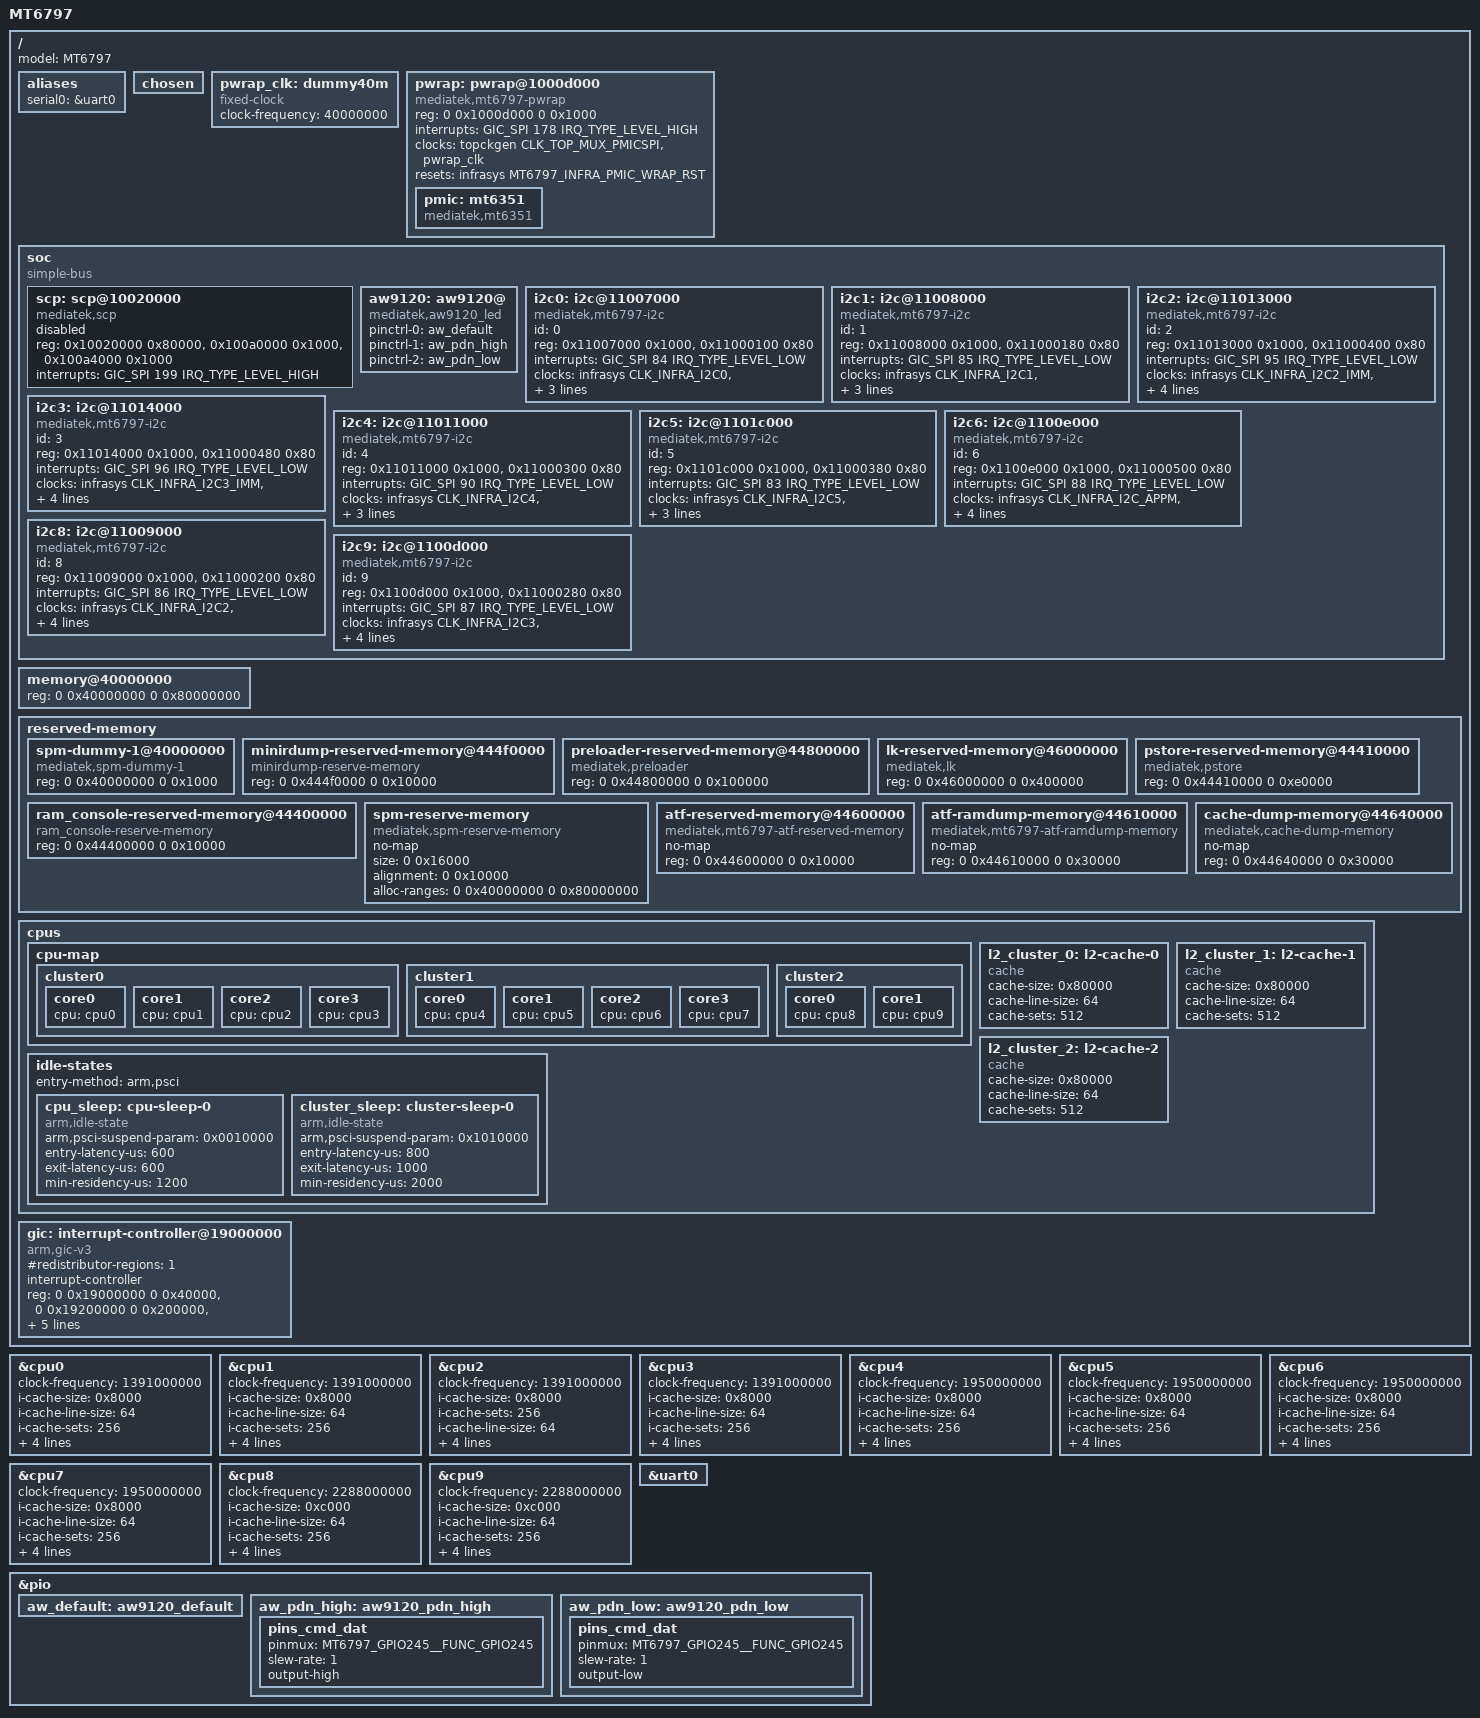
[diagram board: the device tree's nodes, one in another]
// SPDX-License-Identifier: GPL-2.0
/dts-v1/;

#include "mt6797.dtsi"
#include "mt6351.dtsi"
#include <dt-bindings/interrupt-controller/arm-gic.h>
#include <dt-bindings/power/mt6797-power.h>
#include <dt-bindings/reset/mt6797-resets.h>

/ {
	model = "MT6797";

	aliases {
		serial0 = &uart0;
	};

	chosen {
		// Specifying cmdline here is useless, since they are
		// overwritten by LK. CMDLINE is overridden in kernel config.
	};

	// pwrap needs a pwrap clock, but MT6797 does not have one. Make a
	// fake clock to sate the module's hunger.
	pwrap_clk: dummy40m {
		compatible = "fixed-clock";
		clock-frequency = <40000000>;
		#clock-cells = <0>;
	};

	pwrap: pwrap@1000d000 {
		compatible = "mediatek,mt6797-pwrap";
		reg = <0 0x1000d000 0 0x1000>;
		reg-names = "pwrap";
		interrupts = <GIC_SPI 178 IRQ_TYPE_LEVEL_HIGH>;
		clocks = <&topckgen CLK_TOP_MUX_PMICSPI>, <&pwrap_clk>;
		clock-names = "spi", "wrap";
		resets = <&infrasys MT6797_INFRA_PMIC_WRAP_RST>;
		reset-names = "pwrap";
		pmic: mt6351 {
			compatible = "mediatek,mt6351";
		};
	};


	soc {
		compatible = "simple-bus";
		#address-cells = <1>;
		#size-cells = <1>;
		ranges = <0 0 0 0xffffffff>;

		// This node is required by MediaTek's LK bootloader.
		scp: scp@10020000 {
			compatible = "mediatek,scp";
			status = "disabled";
			reg = <0x10020000 0x80000>,
				<0x100a0000 0x1000>,
				<0x100a4000 0x1000>;
			interrupts = <GIC_SPI 199 IRQ_TYPE_LEVEL_HIGH>;
		};

		aw9120: aw9120@ {
			compatible = "mediatek,aw9120_led";
		};

		i2c0:i2c@11007000 {
			compatible = "mediatek,mt6797-i2c";
			id = <0>;
			reg = <0x11007000 0x1000>,
				<0x11000100 0x80>;
			interrupts = <GIC_SPI 84 IRQ_TYPE_LEVEL_LOW>;
			clocks = <&infrasys CLK_INFRA_I2C0>, <&infrasys CLK_INFRA_AP_DMA>;
			clock-names = "main", "dma";
			clock-div = <10>;
		};

		i2c1:i2c@11008000 {
			compatible = "mediatek,mt6797-i2c";
			id = <1>;
			reg = <0x11008000 0x1000>,
				<0x11000180 0x80>;
			interrupts = <GIC_SPI 85 IRQ_TYPE_LEVEL_LOW>;
			clocks = <&infrasys CLK_INFRA_I2C1>, <&infrasys CLK_INFRA_AP_DMA>;
			clock-names = "main", "dma";
			clock-div = <10>;
		};

		i2c2:i2c@11013000 {
			compatible = "mediatek,mt6797-i2c";
			id = <2>;
			reg = <0x11013000 0x1000>,
				<0x11000400 0x80>;
			interrupts = <GIC_SPI 95 IRQ_TYPE_LEVEL_LOW>;
			clocks = <&infrasys CLK_INFRA_I2C2_IMM>, <&infrasys CLK_INFRA_AP_DMA>,
						<&infrasys CLK_INFRA_I2C2_ARB>;
			clock-names = "main", "dma", "arb";
			clock-div = <10>;
		};

		i2c3:i2c@11014000 {
			compatible = "mediatek,mt6797-i2c";
			id = <3>;
			reg = <0x11014000 0x1000>,
				<0x11000480 0x80>;
			interrupts = <GIC_SPI 96 IRQ_TYPE_LEVEL_LOW>;
			clocks = <&infrasys CLK_INFRA_I2C3_IMM>, <&infrasys CLK_INFRA_AP_DMA>,
						<&infrasys CLK_INFRA_I2C3_ARB>;
			clock-names = "main", "dma", "arb";
			clock-div = <10>;
		};

		i2c4:i2c@11011000 {
			compatible = "mediatek,mt6797-i2c";
			id = <4>;
			reg = <0x11011000 0x1000>,
				<0x11000300 0x80>;
			interrupts = <GIC_SPI 90 IRQ_TYPE_LEVEL_LOW>;
			clocks = <&infrasys CLK_INFRA_I2C4>, <&infrasys CLK_INFRA_AP_DMA>;
			clock-names = "main", "dma";
			clock-div = <10>;
		};

		i2c5:i2c@1101c000 {
			compatible = "mediatek,mt6797-i2c";
			id = <5>;
			reg = <0x1101c000 0x1000>,
				<0x11000380 0x80>;
			interrupts = <GIC_SPI 83 IRQ_TYPE_LEVEL_LOW>;
			clocks = <&infrasys CLK_INFRA_I2C5>, <&infrasys CLK_INFRA_AP_DMA>;
			clock-names = "main", "dma";
			clock-div = <10>;
		};

		i2c6:i2c@1100e000 {
			compatible = "mediatek,mt6797-i2c";
			id = <6>;
			reg = <0x1100e000 0x1000>,
				<0x11000500 0x80>;
			interrupts = <GIC_SPI 88 IRQ_TYPE_LEVEL_LOW>;
			clocks = <&infrasys CLK_INFRA_I2C_APPM>, <&infrasys CLK_INFRA_AP_DMA>;
			clock-names = "main", "dma";
			clock-div = <10>;
			mediatek,appm_used;
		};

/* Dissabled for now, needs rt5737
		i2c7:i2c@11010000 {
			compatible = "mediatek,mt6797-i2c";
			id = <7>;
			reg = <0x11010000 0x1000>,
				<0x11000580 0x80>;
			interrupts = <GIC_SPI 89 IRQ_TYPE_LEVEL_LOW>;
			clocks = <&infrasys CLK_INFRA_I2C_GPUPM>, <&infrasys CLK_INFRA_AP_DMA>;
			clock-names = "main", "dma";
			clock-div = <10>;
			mediatek,gpupm_used;

			rt5735@1c {
				status = "ok";
				compatible = "rt,rt5735-regulator";
				reg = <0x1c>;
				//rt,pgdvs;
				//rt,pgdcdc;
				rt,dvs_up = <0x6>;
				rt,dvs_down = <0x1>;
				//rt,dvs_mode;
				rt,ioc = <0x1>;
				rt,tpwth = <0x2>;
				rt,rearm;
			};
		};
*/
		i2c8:i2c@11009000 {
			compatible = "mediatek,mt6797-i2c";
			id = <8>;
			reg = <0x11009000 0x1000>,
				<0x11000200 0x80>;
			interrupts = <GIC_SPI 86 IRQ_TYPE_LEVEL_LOW>;
			clocks = <&infrasys CLK_INFRA_I2C2>, <&infrasys CLK_INFRA_AP_DMA>,
						<&infrasys CLK_INFRA_I2C2_ARB>;
			clock-names = "main", "dma", "arb";
			clock-div = <10>;
			mediatek,buffermode_used;
		};

		i2c9:i2c@1100d000 {
			compatible = "mediatek,mt6797-i2c";
			id = <9>;
			reg = <0x1100d000 0x1000>,
				<0x11000280 0x80>;
			interrupts = <GIC_SPI 87 IRQ_TYPE_LEVEL_LOW>;
			clocks = <&infrasys CLK_INFRA_I2C3>, <&infrasys CLK_INFRA_AP_DMA>,
						<&infrasys CLK_INFRA_I2C3_ARB>;
			clock-names = "main", "dma", "arb";
			clock-div = <10>;
			mediatek,buffermode_used;
		};

	};

	memory@40000000 {
		device_type = "memory";
		// It won't matter much what we write here, since the bootloader
		// overwrites the reg option anyway.
		reg = <0 0x40000000 0 0x80000000>;
	};

	reserved-memory {
		#address-cells = <2>;
		#size-cells = <2>;
		ranges;

		spm-dummy-1@40000000 {
			compatible = "mediatek,spm-dummy-1";
			reg = <0 0x40000000 0 0x1000>;
		};

		minirdump-reserved-memory@444f0000 {
			compatible = "minirdump-reserve-memory";
			reg = <0 0x444f0000 0 0x10000>;
		};

		preloader-reserved-memory@44800000 {
			compatible = "mediatek,preloader";
			reg = <0 0x44800000 0 0x100000>;
		};

		lk-reserved-memory@46000000 {
			compatible = "mediatek,lk";
			reg = <0 0x46000000 0 0x400000>;
		};

		ram_console-reserved-memory@44400000 {
			compatible = "ram_console-reserve-memory";
			reg = <0 0x44400000 0 0x10000>;
		};

		pstore-reserved-memory@44410000 {
			compatible = "mediatek,pstore";
			reg = <0 0x44410000 0 0xe0000>;
			/*console-size = <0 0x40000>;*/
		};

		spm-reserve-memory {
			compatible = "mediatek,spm-reserve-memory";
			no-map;
			size = <0 0x16000>; /* PCM_FIRMWARE_SIZE * DYNA_LOAD_PCM_MAX = 8K * 11 */
			alignment = <0 0x10000>;
			alloc-ranges = <0 0x40000000 0 0x80000000>;
		};

		atf-reserved-memory@44600000 {
			compatible = "mediatek,mt6797-atf-reserved-memory";
			no-map;
			reg = <0 0x44600000 0 0x10000>;
		};

		atf-ramdump-memory@44610000 {
			compatible = "mediatek,mt6797-atf-ramdump-memory";
			no-map;
			reg = <0 0x44610000 0 0x30000>;
		};

		cache-dump-memory@44640000 {
			compatible = "mediatek,cache-dump-memory";
			no-map;
			reg = <0 0x44640000 0 0x30000>;
		};

	};

	cpus {
		cpu-map {
			cluster0 {
				 core0 { cpu = <&cpu0>; };
				 core1 { cpu = <&cpu1>; };
				 core2 { cpu = <&cpu2>; };
				 core3 { cpu = <&cpu3>; };
			};
			cluster1 {
				 core0 { cpu = <&cpu4>; };
				 core1 { cpu = <&cpu5>; };
				 core2 { cpu = <&cpu6>; };
				 core3 { cpu = <&cpu7>; };
			};
			cluster2 {
				 core0 { cpu = <&cpu8>; };
				 core1 { cpu = <&cpu9>; };
			};
		};

		idle-states {
			entry-method = "arm,psci";

			cpu_sleep: cpu-sleep-0 {
				compatible = "arm,idle-state";
				arm,psci-suspend-param = <0x0010000>;
				entry-latency-us = <600>;
				exit-latency-us = <600>;
				min-residency-us = <1200>;
			};
			cluster_sleep: cluster-sleep-0 {
				compatible = "arm,idle-state";
				arm,psci-suspend-param = <0x1010000>;
				entry-latency-us = <800>;
				exit-latency-us = <1000>;
				min-residency-us = <2000>;
			};
		};

		l2_cluster_0: l2-cache-0 {
			compatible = "cache";
			cache-size = <0x80000>;
			cache-line-size = <64>;
			cache-sets = <512>;
		};

		l2_cluster_1: l2-cache-1 {
			compatible = "cache";
			cache-size = <0x80000>;
			cache-line-size = <64>;
			cache-sets = <512>;
		};

		l2_cluster_2: l2-cache-2 {
			compatible = "cache";
			cache-size = <0x80000>;
			cache-line-size = <64>;
			cache-sets = <512>;
		};
	};

	gic: interrupt-controller@19000000 {
		compatible = "arm,gic-v3";
		#interrupt-cells = <3>;
		#address-cells = <2>;
		#size-cells = <2>;
		#redistributor-regions = <1>;
		interrupt-controller;
		reg = <0 0x19000000 0 0x40000>, // distributor
			<0 0x19200000 0 0x200000>, // redistributor
			<0 0x10220620 0 0x001000>, // INTPOL0
			<0 0x10220690 0 0x001000>; // INTPOL1
		interrupts = <GIC_PPI 9 IRQ_TYPE_LEVEL_HIGH>;
		mediatek,wdt_irq = <169>;
		mediatek,reg_len_pol0 = <8>; // 8*32 irq polarity setting in INTPOL0
	};

};

// clock-frequency must be specified for each CPU. If it is omitted, MediaTek's
// LK bootloader might read uninitialized memory and perhaps overwrite some
// random properties in the device tree.

// Slow Cortex-A53 cluster
&cpu0 {
	clock-frequency = <1391000000>;
	//cpu-idle-states = <&cpu_sleep &cluster_sleep>;
	i-cache-size = <0x8000>;
	i-cache-line-size = <64>;
	i-cache-sets = <256>;
	d-cache-size = <0x8000>;
	d-cache-line-size = <64>;
	d-cache-sets = <128>;
	next-level-cache = <&l2_cluster_0>;
};
&cpu1 {
	clock-frequency = <1391000000>;
	//cpu-idle-states = <&cpu_sleep &cluster_sleep>;
	i-cache-size = <0x8000>;
	i-cache-line-size = <64>;
	i-cache-sets = <256>;
	d-cache-size = <0x8000>;
	d-cache-line-size = <64>;
	d-cache-sets = <128>;
	next-level-cache = <&l2_cluster_0>;
};
&cpu2 {
	clock-frequency = <1391000000>;
	//cpu-idle-states = <&cpu_sleep &cluster_sleep>;
	i-cache-size = <0x8000>;
	i-cache-sets = <256>;
	i-cache-line-size = <64>;
	d-cache-size = <0x8000>;
	d-cache-line-size = <64>;
	d-cache-sets = <128>;
	next-level-cache = <&l2_cluster_0>;
};
&cpu3 {
	clock-frequency = <1391000000>;
	//cpu-idle-states = <&cpu_sleep &cluster_sleep>;
	i-cache-size = <0x8000>;
	i-cache-line-size = <64>;
	i-cache-sets = <256>;
	d-cache-size = <0x8000>;
	d-cache-line-size = <64>;
	d-cache-sets = <128>;
	next-level-cache = <&l2_cluster_0>;
};

// Fast Cortex-A53 cluster
&cpu4 {
	clock-frequency = <1950000000>;
	//cpu-idle-states = <&cpu_sleep &cluster_sleep>;
	i-cache-size = <0x8000>;
	i-cache-line-size = <64>;
	i-cache-sets = <256>;
	d-cache-size = <0x8000>;
	d-cache-line-size = <64>;
	d-cache-sets = <128>;
	next-level-cache = <&l2_cluster_1>;
};
&cpu5 {
	clock-frequency = <1950000000>;
	//cpu-idle-states = <&cpu_sleep &cluster_sleep>;
	i-cache-size = <0x8000>;
	i-cache-line-size = <64>;
	i-cache-sets = <256>;
	d-cache-size = <0x8000>;
	d-cache-line-size = <64>;
	d-cache-sets = <128>;
	next-level-cache = <&l2_cluster_1>;
};
&cpu6 {
	clock-frequency = <1950000000>;
	//cpu-idle-states = <&cpu_sleep &cluster_sleep>;
	i-cache-size = <0x8000>;
	i-cache-line-size = <64>;
	i-cache-sets = <256>;
	d-cache-size = <0x8000>;
	d-cache-line-size = <64>;
	d-cache-sets = <128>;
	next-level-cache = <&l2_cluster_1>;
};
&cpu7 {
	clock-frequency = <1950000000>;
	//cpu-idle-states = <&cpu_sleep &cluster_sleep>;
	i-cache-size = <0x8000>;
	i-cache-line-size = <64>;
	i-cache-sets = <256>;
	d-cache-size = <0x8000>;
	d-cache-line-size = <64>;
	d-cache-sets = <128>;
	next-level-cache = <&l2_cluster_1>;
};

// Fast Cortex-A72 cluster
&cpu8 {
	clock-frequency = <2288000000>;
	//cpu-idle-states = <&cpu_sleep &cluster_sleep>;

	i-cache-size = <0xc000>;
	i-cache-line-size = <64>;
	i-cache-sets = <256>;

	d-cache-size = <0x8000>;
	d-cache-line-size = <64>;
	d-cache-sets = <256>;
	next-level-cache = <&l2_cluster_2>;
};
&cpu9 {
	clock-frequency = <2288000000>;
	//cpu-idle-states = <&cpu_sleep &cluster_sleep>;

	i-cache-size = <0xc000>;
	i-cache-line-size = <64>;
	i-cache-sets = <256>;

	d-cache-size = <0x8000>;
	d-cache-line-size = <64>;
	d-cache-sets = <256>;
	next-level-cache = <&l2_cluster_2>;
};

&uart0 {
	status = "okay";
};

&i2c0 {
	pinctrl-names = "default";
	pinctrl-0 = <&i2c_pins_0>;
	status = "okay";
};

&i2c1 {
	pinctrl-names = "default";
	pinctrl-0 = <&i2c_pins_1>;
	status = "okay";
};

&i2c2 {
	pinctrl-names = "default";
	pinctrl-0 = <&i2c_pins_2>;
	status = "okay";
};

&i2c3 {
	pinctrl-names = "default";
	pinctrl-0 = <&i2c_pins_3>;
	status = "okay";
};

&i2c4 {
	pinctrl-names = "default";
	pinctrl-0 = <&i2c_pins_4>;
	status = "okay";
};

&i2c5 {
	pinctrl-names = "default";
	pinctrl-0 = <&i2c_pins_5>;
	status = "okay";
};

&i2c6 {
	pinctrl-names = "default";
	pinctrl-0 = <&i2c_pins_6>;
	status = "okay";
};

/* Dissabled for now, needs rt5737
&i2c7 {
	pinctrl-names = "default";
	pinctrl-0 = <&i2c_pins_7>;
	status = "okay";
};
*/

&aw9120 {
	pinctrl-names = "aw9120_default", "aw9120_pdn_high", "aw9120_pdn_low";
	pinctrl-0 = <&aw_default>;
	pinctrl-1 = <&aw_pdn_high>;
	pinctrl-2 = <&aw_pdn_low>;
	status = "okay";
};
&pio {
	aw_default: aw9120_default {
	};

	aw_pdn_high: aw9120_pdn_high {
		pins_cmd_dat {
			pinmux = <MT6797_GPIO245__FUNC_GPIO245>;
			slew-rate = <1>;
			output-high;
		};
	};
	aw_pdn_low: aw9120_pdn_low {
		pins_cmd_dat {
			pinmux = <MT6797_GPIO245__FUNC_GPIO245>;
			slew-rate = <1>;
			output-low;
		};
	};
};
